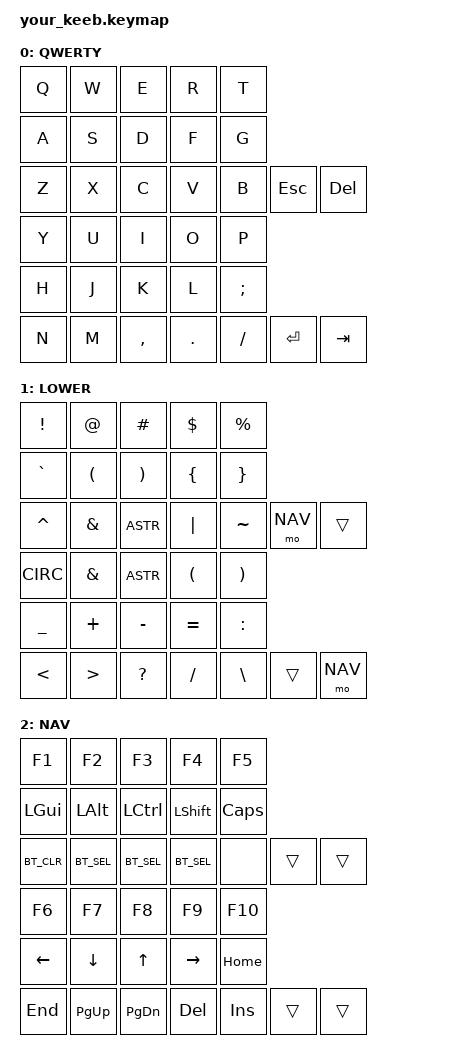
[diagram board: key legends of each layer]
#include <behaviors.dtsi>
#include <dt-bindings/zmk/keys.h>
#include <dt-bindings/zmk/bt.h>

/ {
    keymap {
        compatible = "zmk,keymap";

        default_layer {
            label = "QWERTY";
            bindings = <
    // Left Side - Row 1
    &kp Q  &kp W  &kp E  &kp R  &kp T  
    // Left Side - Row 2  
    &kp A  &kp S  &kp D  &kp F  &kp G
    // Left Side - Row 3
    &kp Z  &kp X  &kp C  &kp V  &kp B  &kp ESC &kp DEL

    // Right Side - Row 1
    &kp Y  &kp U  &kp I  &kp O  &kp P
    // Right Side - Row 2
    &kp H  &kp J  &kp K  &kp L  &kp SEMI
    // Right Side - Row 3  
    &kp N  &kp M  &kp COMMA &kp DOT &kp SLASH &kp RET &kp TAB
            >;
        };

        lower_layer {
            label = "LOWER";
            bindings = <
    // Left Side - Row 1
    &kp EXCL  &kp AT  &kp HASH  &kp DLLR  &kp PRCNT
    // Left Side - Row 2
    &kp GRAVE  &kp LPAR  &kp RPAR  &kp LBRC  &kp RBRC  
    // Left Side - Row 3
    &kp CARET  &kp AMPS  &kp ASTR  &kp PIPE  &kp TILDE  &mo NAV &trans

    // Right Side - Row 1
    &kp CIRC  &kp AMPS  &kp ASTR  &kp LPRN  &kp RPRN
    // Right Side - Row 2  
    &kp UNDER  &kp PLUS  &kp MINUS  &kp EQL  &kp COLON
    // Right Side - Row 3
    &kp LT  &kp GT  &kp QUESTION  &kp SLASH  &kp BSLH  &trans &mo NAV
            >;
        };

        nav_layer {
            label = "NAV";
            bindings = <
    // Left Side - Row 1
    &kp F1  &kp F2  &kp F3  &kp F4  &kp F5
    // Left Side - Row 2
    &kp LGUI  &kp LALT  &kp LCTRL  &kp LSHFT  &kp CAPS
    // Left Side - Row 3
    &kp BT_CLR  &kp BT_SEL 0  &kp BT_SEL 1  &kp BT_SEL 2  &none  &trans &trans

    // Right Side - Row 1
    &kp F6  &kp F7  &kp F8  &kp F9  &kp F10
    // Right Side - Row 2
    &kp LEFT  &kp DOWN  &kp UP  &kp RIGHT  &kp HOME
    // Right Side - Row 3
    &kp END  &kp PG_UP  &kp PG_DN  &kp DEL  &kp INS  &trans &trans
            >;
        };
    };
};
